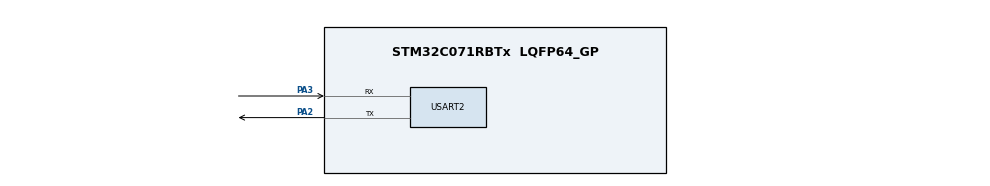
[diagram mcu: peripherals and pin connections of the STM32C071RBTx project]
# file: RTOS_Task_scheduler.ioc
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Mcu.Family=STM32C0
Mcu.Name=STM32C071RBTx
Mcu.Package=LQFP64_GP
NVIC.USART2_IRQn=true\:0\:0\:false\:false\:true\:true\:true\:true
PA2.Mode=Asynchronous
PA2.Signal=USART2_TX
PA3.Mode=Asynchronous
PA3.Signal=USART2_RX
ProjectManager.HeapSize=0x200
ProjectManager.StackSize=0x400
ProjectManager.TargetToolchain=STM32CubeIDE
RCC.ADCFreq_Value=48000000
RCC.AHBFreq_Value=48000000
RCC.CortexFreq_Value=48000000
RCC.EXTERNAL_CLOCK_VALUE=12288000
RCC.HCLKFreq_Value=48000000
RCC.HSE_VALUE=8000000
RCC.HSI48_VALUE=48000000
RCC.HSISYSCLKDivider=RCC_HSI_DIV1
RCC.HSI_VALUE=48000000
RCC.LSE_VALUE=32768
RCC.SYSCLKFreq_VALUE=48000000
TIM2.Prescaler=48-1
USART2.VirtualMode-Asynchronous=VM_ASYNC
VP_TIM2_VS_ClockSourceINT.Mode=Internal
board=NUCLEO-C071RB

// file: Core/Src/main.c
/* USER CODE BEGIN Header */
/**
  ******************************************************************************
  * @file           : main.c
  * @brief          : Main program body
  ******************************************************************************
  * @attention
  *
  * Copyright (c) 2025 STMicroelectronics.
  * All rights reserved.
  *
  * This software is licensed under terms that can be found in the LICENSE file
  * in the root directory of this software component.
  * If no LICENSE file comes with this software, it is provided AS-IS.
  *
  ******************************************************************************
  */
/* USER CODE END Header */
#include "main.h"
#include "tim.h"
#include "usart.h"
#include "gpio.h"

/* USER CODE BEGIN Includes */
#include "logger.h"
#include "scheduler.h"
#include "tasks.h"
#include "usart.h"
/* USER CODE END Includes */

void SystemClock_Config(void);

int main(void)
{

  /* MCU Configuration--------------------------------------------------------*/

  /* Reset of all peripherals, Initializes the Flash interface and the Systick. */
  HAL_Init();

  /* Configure the system clock */
  SystemClock_Config();

  /* Initialize all configured peripherals */
  MX_GPIO_Init();
  MX_USART2_UART_Init();
  MX_TIM2_Init();
  /* USER CODE BEGIN 2 */

  HAL_TIM_Base_Start(&htim2);
  scheduler_init();

  create_task(task1, NULL, 5); // lowest priority
  create_task(task2, NULL, 1); // highest priority
  create_task(task3, NULL, 2); // middle priority

  /* USER CODE END 2 */

  /* Infinite loop */
  /* USER CODE BEGIN WHILE */
  while (1)
  {
	  scheduler_run();
	   __WFI(); // Wait for interrupt; sleep (low power mode) when no task is ready until interrupt occurs or task gets ready

	  if (scheduler_all_tasks_done()) {

		  scheduler_reset_all_tasks();

	     }
  }

}
    /* USER CODE END WHILE */

void SystemClock_Config(void)
{
  RCC_OscInitTypeDef RCC_OscInitStruct = {0};
  RCC_ClkInitTypeDef RCC_ClkInitStruct = {0};

  __HAL_FLASH_SET_LATENCY(FLASH_LATENCY_1);

  /** Initializes the RCC Oscillators according to the specified parameters
  * in the RCC_OscInitTypeDef structure.
  */
  RCC_OscInitStruct.OscillatorType = RCC_OSCILLATORTYPE_HSI;
  RCC_OscInitStruct.HSIState = RCC_HSI_ON;
  RCC_OscInitStruct.HSIDiv = RCC_HSI_DIV1;
  RCC_OscInitStruct.HSICalibrationValue = RCC_HSICALIBRATION_DEFAULT;
  if (HAL_RCC_OscConfig(&RCC_OscInitStruct) != HAL_OK)
  {
    Error_Handler();
  }

  /** Initializes the CPU, AHB and APB buses clocks
  */
  RCC_ClkInitStruct.ClockType = RCC_CLOCKTYPE_HCLK|RCC_CLOCKTYPE_SYSCLK
                              |RCC_CLOCKTYPE_PCLK1;
  RCC_ClkInitStruct.SYSCLKSource = RCC_SYSCLKSOURCE_HSI;
  RCC_ClkInitStruct.SYSCLKDivider = RCC_SYSCLK_DIV1;
  RCC_ClkInitStruct.AHBCLKDivider = RCC_HCLK_DIV1;
  RCC_ClkInitStruct.APB1CLKDivider = RCC_APB1_DIV1;

  if (HAL_RCC_ClockConfig(&RCC_ClkInitStruct, FLASH_LATENCY_1) != HAL_OK)
  {
    Error_Handler();
  }
}

void Error_Handler(void)
{
  __disable_irq();
  while (1)
  {
  }
}
